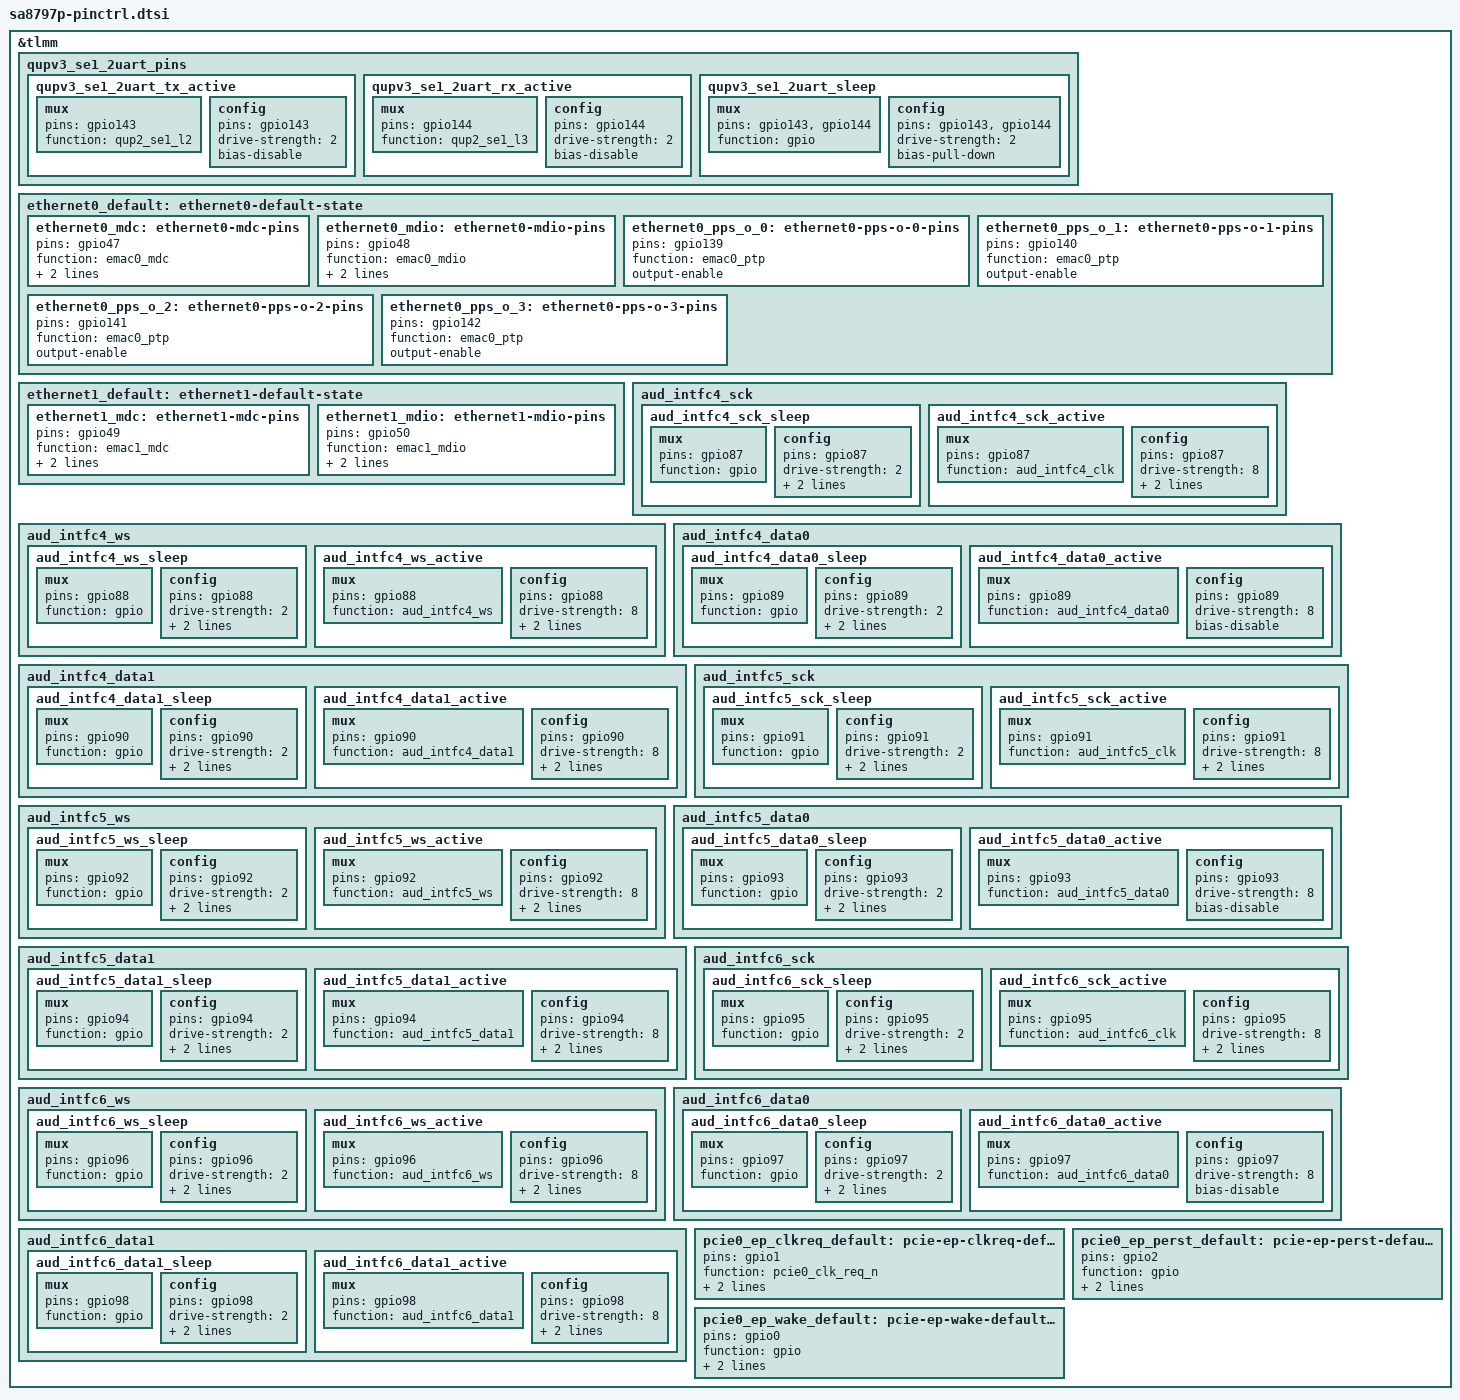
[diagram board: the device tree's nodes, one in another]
// SPDX-License-Identifier: BSD-3-Clause
/*
 * Copyright (c) Qualcomm Technologies, Inc. and/or its subsidiaries.
 */

&tlmm {
	qupv3_se1_2uart_pins: qupv3_se1_2uart_pins {
		qupv3_se1_2uart_tx_active: qupv3_se1_2uart_tx_active {
			mux {
				pins = "gpio143";
				function = "qup2_se1_l2";
			};

			config {
				pins = "gpio143";
				drive-strength = <2>;
				bias-disable;
			};
		};

		qupv3_se1_2uart_rx_active: qupv3_se1_2uart_rx_active {
			mux {
				pins = "gpio144";
				function = "qup2_se1_l3";
			};

			config {
				pins = "gpio144";
				drive-strength = <2>;
				bias-disable;
			};
		};

		qupv3_se1_2uart_sleep: qupv3_se1_2uart_sleep {
			mux {
				pins = "gpio143", "gpio144";
				function = "gpio";
			};

			config {
				pins = "gpio143", "gpio144";
				drive-strength = <2>;
				bias-pull-down;
			};
		};
	};

	ethernet0_default: ethernet0-default-state {
		ethernet0_mdc: ethernet0-mdc-pins {
			pins = "gpio47";
			function = "emac0_mdc";
			drive-strength = <16>;
			bias-pull-up;
		};

		ethernet0_mdio: ethernet0-mdio-pins {
			pins = "gpio48";
			function = "emac0_mdio";
			drive-strength = <16>;
			bias-pull-up;
		};

		ethernet0_pps_o_0: ethernet0-pps-o-0-pins {
			pins = "gpio139";
			function = "emac0_ptp";
			output-enable;
		};

		ethernet0_pps_o_1: ethernet0-pps-o-1-pins {
			pins = "gpio140";
			function = "emac0_ptp";
			output-enable;
		};

		ethernet0_pps_o_2: ethernet0-pps-o-2-pins {
			pins = "gpio141";
			function = "emac0_ptp";
			output-enable;
		};

		ethernet0_pps_o_3: ethernet0-pps-o-3-pins {
			pins = "gpio142";
			function = "emac0_ptp";
			output-enable;
		};
	};

	ethernet1_default: ethernet1-default-state {
		ethernet1_mdc: ethernet1-mdc-pins {
			pins = "gpio49";
			function = "emac1_mdc";
			drive-strength = <16>;
			bias-pull-up;
		};

		ethernet1_mdio: ethernet1-mdio-pins {
			pins = "gpio50";
			function = "emac1_mdio";
			drive-strength = <16>;
			bias-pull-up;
		};
	};

	aud_intfc4_sck {
		aud_intfc4_sck_sleep: aud_intfc4_sck_sleep {
			mux {
				pins = "gpio87";
				function = "gpio";
			};

			config {
				pins = "gpio87";
				drive-strength = <2>;   /* 2 mA */
				bias-pull-down;         /* PULL DOWN */
				input-enable;
			};
		};

		aud_intfc4_sck_active: aud_intfc4_sck_active {
			mux {
				pins = "gpio87";
				function = "aud_intfc4_clk";
			};

			config {
				pins = "gpio87";
				drive-strength = <8>;   /* 8 mA */
				bias-disable;           /* NO PULL */
				output-high;
			};
		};
	};

	aud_intfc4_ws {
		aud_intfc4_ws_sleep: aud_intfc4_ws_sleep {
			mux {
				pins = "gpio88";
				function = "gpio";
			};

			config {
				pins = "gpio88";
				drive-strength = <2>;   /* 2 mA */
				bias-pull-down;         /* PULL DOWN */
				input-enable;
			};
		};

		aud_intfc4_ws_active: aud_intfc4_ws_active {
			mux {
				pins = "gpio88";
				function = "aud_intfc4_ws";
			};

			config {
				pins = "gpio88";
				drive-strength = <8>;   /* 8 mA */
				bias-disable;           /* NO PULL */
				output-high;
			};
		};
	};

	aud_intfc4_data0 {
		aud_intfc4_data0_sleep: aud_intfc4_data0_sleep {
			mux {
				pins = "gpio89";
				function = "gpio";
			};

			config {
				pins = "gpio89";
				drive-strength = <2>;   /* 2 mA */
				bias-pull-down;         /* PULL DOWN */
				input-enable;
			};
		};

		aud_intfc4_data0_active: aud_intfc4_data0_active {
			mux {
				pins = "gpio89";
				function = "aud_intfc4_data0";
			};

			config {
				pins = "gpio89";
				drive-strength = <8>;   /* 8 mA */
				bias-disable;           /* NO PULL */
			};
		};
	};

	aud_intfc4_data1 {
		aud_intfc4_data1_sleep: aud_intfc4_data1_sleep {
			mux {
				pins = "gpio90";
				function = "gpio";
			};

			config {
				pins = "gpio90";
				drive-strength = <2>;   /* 2 mA */
				bias-pull-down;         /* PULL DOWN */
				input-enable;
			};
		};

		aud_intfc4_data1_active: aud_intfc4_data1_active {
			mux {
				pins = "gpio90";
				function = "aud_intfc4_data1";
			};

			config {
				pins = "gpio90";
				drive-strength = <8>;   /* 8 mA */
				bias-disable;           /* NO PULL */
				output-high;
			};
		};
	};

	aud_intfc5_sck {
		aud_intfc5_sck_sleep: aud_intfc5_sck_sleep {
			mux {
				pins = "gpio91";
				function = "gpio";
			};

			config {
				pins = "gpio91";
				drive-strength = <2>;   /* 2 mA */
				bias-pull-down;         /* PULL DOWN */
				input-enable;
			};
		};

		aud_intfc5_sck_active: aud_intfc5_sck_active {
			mux {
				pins = "gpio91";
				function = "aud_intfc5_clk";
			};

			config {
				pins = "gpio91";
				drive-strength = <8>;   /* 8 mA */
				bias-disable;           /* NO PULL */
				output-high;
			};
		};
	};

	aud_intfc5_ws {
		aud_intfc5_ws_sleep: aud_intfc5_ws_sleep {
			mux {
				pins = "gpio92";
				function = "gpio";
			};

			config {
				pins = "gpio92";
				drive-strength = <2>;   /* 2 mA */
				bias-pull-down;         /* PULL DOWN */
				input-enable;
			};
		};

		aud_intfc5_ws_active: aud_intfc5_ws_active {
			mux {
				pins = "gpio92";
				function = "aud_intfc5_ws";
			};

			config {
				pins = "gpio92";
				drive-strength = <8>;   /* 8 mA */
				bias-disable;           /* NO PULL */
				output-high;
			};
		};
	};

	aud_intfc5_data0 {
		aud_intfc5_data0_sleep: aud_intfc5_data0_sleep {
			mux {
				pins = "gpio93";
				function = "gpio";
			};

			config {
				pins = "gpio93";
				drive-strength = <2>;   /* 2 mA */
				bias-pull-down;         /* PULL DOWN */
				input-enable;
			};
		};

		aud_intfc5_data0_active: aud_intfc5_data0_active {
			mux {
				pins = "gpio93";
				function = "aud_intfc5_data0";
			};

			config {
				pins = "gpio93";
				drive-strength = <8>;   /* 8 mA */
				bias-disable;           /* NO PULL */
			};
		};
	};

	aud_intfc5_data1 {
		aud_intfc5_data1_sleep: aud_intfc5_data1_sleep {
			mux {
				pins = "gpio94";
				function = "gpio";
			};

			config {
				pins = "gpio94";
				drive-strength = <2>;   /* 2 mA */
				bias-pull-down;         /* PULL DOWN */
				input-enable;
			};
		};

		aud_intfc5_data1_active: aud_intfc5_data1_active {
			mux {
				pins = "gpio94";
				function = "aud_intfc5_data1";
			};

			config {
				pins = "gpio94";
				drive-strength = <8>;   /* 8 mA */
				bias-disable;           /* NO PULL */
				output-high;
			};
		};
	};

	aud_intfc6_sck {
		aud_intfc6_sck_sleep: aud_intfc6_sck_sleep {
			mux {
				pins = "gpio95";
				function = "gpio";
			};

			config {
				pins = "gpio95";
				drive-strength = <2>;   /* 2 mA */
				bias-pull-down;         /* PULL DOWN */
				input-enable;
			};
		};

		aud_intfc6_sck_active: aud_intfc6_sck_active {
			mux {
				pins = "gpio95";
				function = "aud_intfc6_clk";
			};

			config {
				pins = "gpio95";
				drive-strength = <8>;   /* 8 mA */
				bias-disable;           /* NO PULL */
				output-high;
			};
		};
	};

	aud_intfc6_ws {
		aud_intfc6_ws_sleep: aud_intfc6_ws_sleep {
			mux {
				pins = "gpio96";
				function = "gpio";
			};

			config {
				pins = "gpio96";
				drive-strength = <2>;   /* 2 mA */
				bias-pull-down;         /* PULL DOWN */
				input-enable;
			};
		};

		aud_intfc6_ws_active: aud_intfc6_ws_active {
			mux {
				pins = "gpio96";
				function = "aud_intfc6_ws";
			};

			config {
				pins = "gpio96";
				drive-strength = <8>;   /* 8 mA */
				bias-disable;           /* NO PULL */
				output-high;
			};
		};
	};

	aud_intfc6_data0 {
		aud_intfc6_data0_sleep: aud_intfc6_data0_sleep {
			mux {
				pins = "gpio97";
				function = "gpio";
			};

			config {
				pins = "gpio97";
				drive-strength = <2>;   /* 2 mA */
				bias-pull-down;         /* PULL DOWN */
				input-enable;
			};
		};

		aud_intfc6_data0_active: aud_intfc6_data0_active {
			mux {
				pins = "gpio97";
				function = "aud_intfc6_data0";
			};

			config {
				pins = "gpio97";
				drive-strength = <8>;   /* 8 mA */
				bias-disable;           /* NO PULL */
			};
		};
	};

	aud_intfc6_data1 {
		aud_intfc6_data1_sleep: aud_intfc6_data1_sleep {
			mux {
				pins = "gpio98";
				function = "gpio";
			};

			config {
				pins = "gpio98";
				drive-strength = <2>;   /* 2 mA */
				bias-pull-down;         /* PULL DOWN */
				input-enable;
			};
		};

		aud_intfc6_data1_active: aud_intfc6_data1_active {
			mux {
				pins = "gpio98";
				function = "aud_intfc6_data1";
			};

			config {
				pins = "gpio98";
				drive-strength = <8>;   /* 8 mA */
				bias-disable;           /* NO PULL */
				output-high;
			};
		};
	};

	pcie0_ep_clkreq_default: pcie-ep-clkreq-default-state {
		pins = "gpio1";
		function = "pcie0_clk_req_n";
		drive-strength = <2>;
		bias-disable;
	};

	pcie0_ep_perst_default: pcie-ep-perst-default-state {
		pins = "gpio2";
		function = "gpio";
		drive-strength = <16>;
		bias-pull-down;
	};

	pcie0_ep_wake_default: pcie-ep-wake-default-state {
		pins = "gpio0";
		function = "gpio";
		drive-strength = <2>;
		bias-disable;
	};
};
